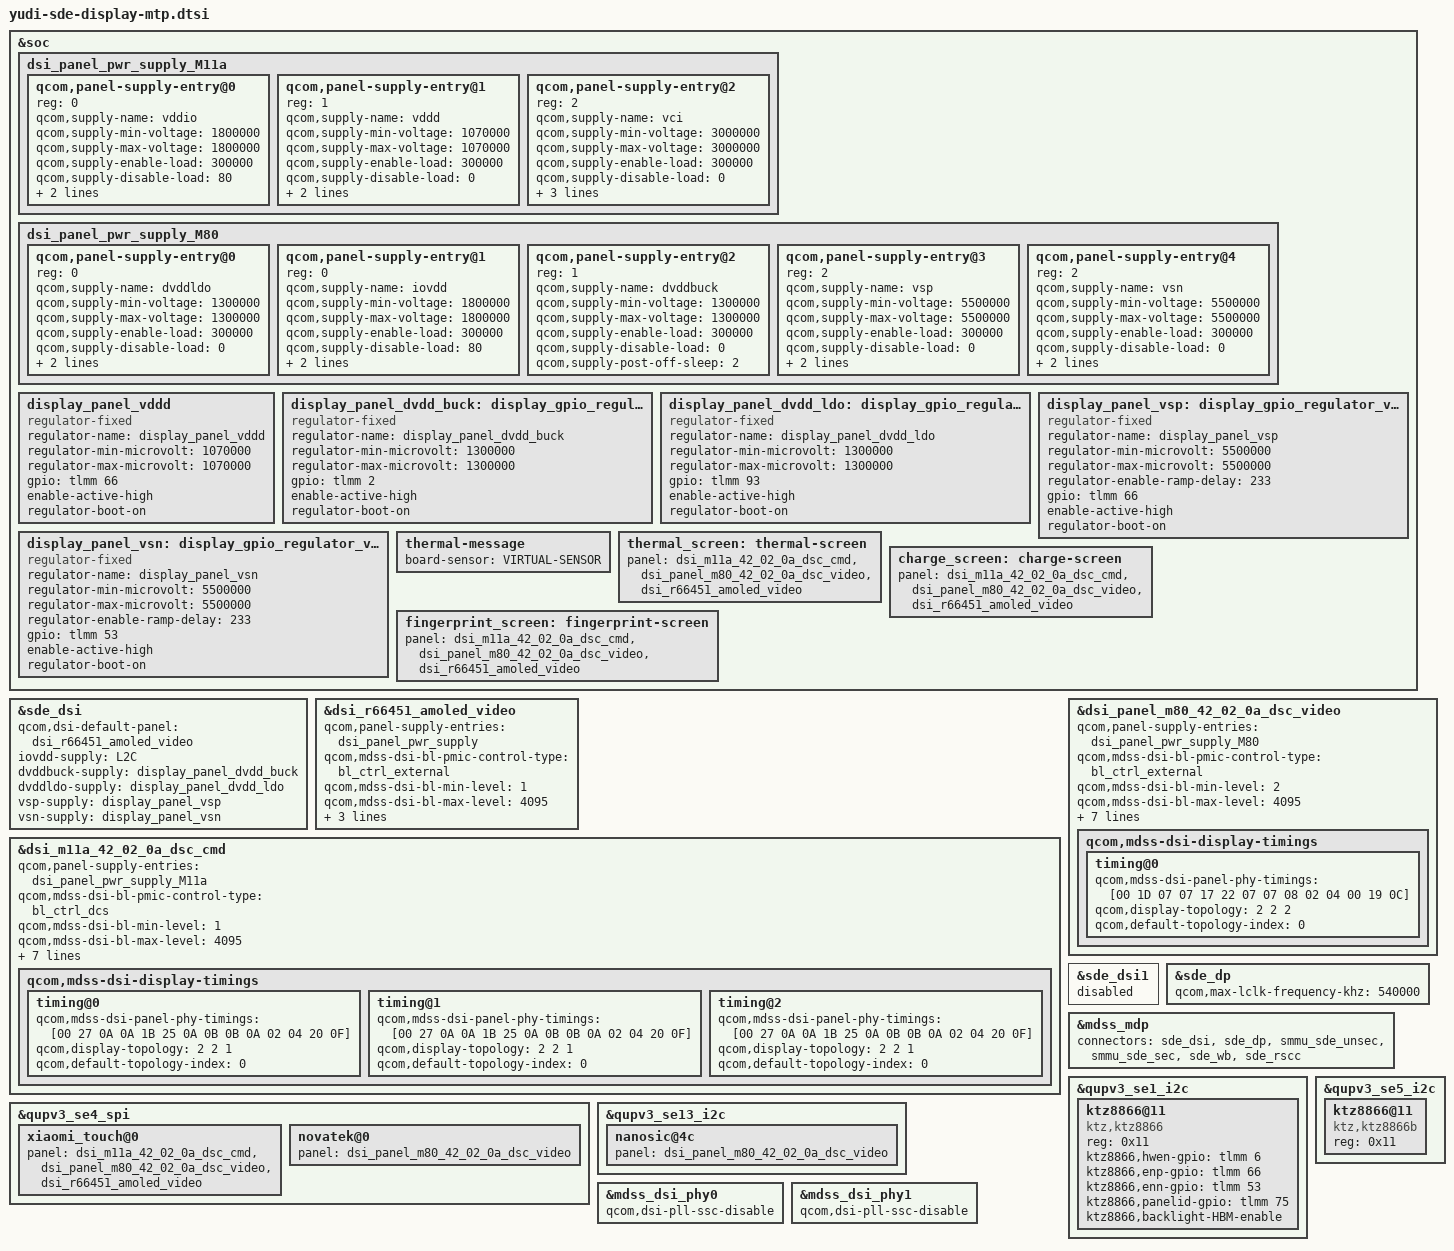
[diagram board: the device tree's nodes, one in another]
#include "cape-sde-display.dtsi"
#include "dsi-panel-m11a-42-02-0a-dsc-cmd.dtsi"
#include "dsi-panel-m80-42-02-0a-dsc-video.dtsi"

&soc {
	dsi_panel_pwr_supply_M11a: dsi_panel_pwr_supply_M11a {
		#address-cells = <1>;
		#size-cells = <0>;
		qcom,panel-supply-entry@0 {
			reg = <0>;
			qcom,supply-name = "vddio";
			qcom,supply-min-voltage = <1800000>;
			qcom,supply-max-voltage = <1800000>;
			qcom,supply-enable-load = <300000>;
			qcom,supply-disable-load = <80>;
			qcom,supply-post-on-sleep = <20>;
			qcom,supply-post-off-sleep = <10>;
		};
		qcom,panel-supply-entry@1 {
			reg = <1>;
			qcom,supply-name = "vddd";
			qcom,supply-min-voltage = <1070000>;
			qcom,supply-max-voltage = <1070000>;
			qcom,supply-enable-load = <300000>;
			qcom,supply-disable-load = <0>;
			qcom,supply-post-on-sleep = <20>;
			qcom,supply-post-off-sleep = <10>;
		};
		qcom,panel-supply-entry@2 {
			reg = <2>;
			qcom,supply-name = "vci";
			qcom,supply-min-voltage = <3000000>;
			qcom,supply-max-voltage = <3000000>;
			qcom,supply-enable-load = <300000>;
			qcom,supply-disable-load = <0>;
			qcom,supply-post-on-sleep = <15>;
			qcom,supply-pre-on-sleep = <10>;
			qcom,supply-post-off-sleep = <10>;
		};
	};
};

&soc {
	dsi_panel_pwr_supply_M80: dsi_panel_pwr_supply_M80 {
		#address-cells = <1>;
		#size-cells = <0>;
		qcom,panel-supply-entry@0 {
			reg = <0>;
			qcom,supply-name = "dvddldo";
			qcom,supply-min-voltage = <1300000>;
			qcom,supply-max-voltage = <1300000>;
			qcom,supply-enable-load = <300000>;
			qcom,supply-disable-load = <0>;
			qcom,supply-post-on-sleep = <1>;
			qcom,supply-post-off-sleep = <1>;
		};

		qcom,panel-supply-entry@1 {
			reg = <0>;
			qcom,supply-name = "iovdd";
			qcom,supply-min-voltage = <1800000>;
			qcom,supply-max-voltage = <1800000>;
			qcom,supply-enable-load = <300000>;
			qcom,supply-disable-load = <80>;
			qcom,supply-post-on-sleep = <2>;
			qcom,supply-post-off-sleep = <2>;
		};
		qcom,panel-supply-entry@2 {
			reg = <1>;
			qcom,supply-name = "dvddbuck";
			qcom,supply-min-voltage = <1300000>;
			qcom,supply-max-voltage = <1300000>;
			qcom,supply-enable-load = <300000>;
			qcom,supply-disable-load = <0>;
			qcom,supply-post-off-sleep = <2>;
		};

		qcom,panel-supply-entry@3 {
			reg = <2>;
			qcom,supply-name = "vsp";
			qcom,supply-min-voltage = <5500000>;
			qcom,supply-max-voltage = <5500000>;
			qcom,supply-enable-load = <300000>;
			qcom,supply-disable-load = <0>;
			qcom,supply-post-on-sleep = <2>;
			qcom,supply-post-off-sleep = <2>;
		};

		qcom,panel-supply-entry@4 {
			reg = <2>;
			qcom,supply-name = "vsn";
			qcom,supply-min-voltage = <5500000>;
			qcom,supply-max-voltage = <5500000>;
			qcom,supply-enable-load = <300000>;
			qcom,supply-disable-load = <0>;
			qcom,supply-post-on-sleep = <2>;
			qcom,supply-post-off-sleep = <2>;
		};
	};
};

&soc {
	display_panel_vddd: display_panel_vddd {
		compatible = "regulator-fixed";
		regulator-name = "display_panel_vddd";
		regulator-min-microvolt = <1070000>;
		regulator-max-microvolt = <1070000>;
		gpio = <&tlmm 66 0>;
		enable-active-high;
		regulator-boot-on;
	};
	
	display_panel_dvdd_buck: display_gpio_regulator_dvdd_buck {
		compatible = "regulator-fixed";
		regulator-name = "display_panel_dvdd_buck";
		regulator-min-microvolt = <1300000>;
		regulator-max-microvolt = <1300000>;
		gpio = <&tlmm 2 0>;
		enable-active-high;
		regulator-boot-on;
	};

	display_panel_dvdd_ldo: display_gpio_regulator_dvdd_ldo {
		compatible = "regulator-fixed";
		regulator-name = "display_panel_dvdd_ldo";
		regulator-min-microvolt = <1300000>;
		regulator-max-microvolt = <1300000>;
		gpio = <&tlmm 93 0>;
		enable-active-high;
		regulator-boot-on;
	};

	display_panel_vsp: display_gpio_regulator_vsp {
		compatible = "regulator-fixed";
		regulator-name = "display_panel_vsp";
		regulator-min-microvolt = <5500000>;
		regulator-max-microvolt = <5500000>;
		regulator-enable-ramp-delay = <233>;
		gpio = <&tlmm 66 0>;
		enable-active-high;
		regulator-boot-on;
	};

	display_panel_vsn: display_gpio_regulator_vsn {
		compatible = "regulator-fixed";
		regulator-name = "display_panel_vsn";
		regulator-min-microvolt = <5500000>;
		regulator-max-microvolt = <5500000>;
		regulator-enable-ramp-delay = <233>;
		gpio = <&tlmm 53 0>;
		enable-active-high;
		regulator-boot-on;
	};
};
&sde_dsi {
	qcom,dsi-default-panel = <&dsi_r66451_amoled_video>;
	iovdd-supply = <&L2C>;
	dvddbuck-supply = <&display_panel_dvdd_buck>;
	dvddldo-supply = <&display_panel_dvdd_ldo>;
	vsp-supply = <&display_panel_vsp>;
	vsn-supply = <&display_panel_vsn>;
};
&dsi_r66451_amoled_video {
	qcom,panel-supply-entries = <&dsi_panel_pwr_supply>;
	qcom,mdss-dsi-bl-pmic-control-type = "bl_ctrl_external";
	qcom,mdss-dsi-bl-min-level = <1>;
	qcom,mdss-dsi-bl-max-level = <4095>;
	qcom,mdss-brightness-max-level = <255>;
	qcom,mdss-dsi-bl-inverted-dbv;
	qcom,platform-reset-gpio = <&tlmm 0 0>;
};
&dsi_m11a_42_02_0a_dsc_cmd {
	qcom,panel-supply-entries = <&dsi_panel_pwr_supply_M11a>;
	qcom,mdss-dsi-bl-pmic-control-type = "bl_ctrl_dcs";
	qcom,mdss-dsi-bl-min-level = <1>;
	qcom,mdss-dsi-bl-max-level = <4095>;
	qcom,mdss-brightness-max-level = <4095>;
	qcom,mdss-dsi-bl-inverted-dbv;
	qcom,platform-reset-gpio = <&tlmm 0 0>;
};
&dsi_m11a_42_02_0a_dsc_cmd  {
	qcom,ulps-enabled;
	qcom,mdss-dsi-panel-vsync-delay;
	qcom,dsi-select-clocks = "pll_byte_clk0", "pll_dsi_clk0";
		qcom,mdss-dsi-display-timings {
		/* 60 Hz */
		timing@0{
			qcom,mdss-dsi-panel-phy-timings = [00 27 0A 0A 1B 25 0A
				0B 0B 0A 02 04 20 0F];
			qcom,display-topology = <2 2 1>;
			qcom,default-topology-index = <0>;
		};
		/* 90Hz */
		timing@1{
				qcom,mdss-dsi-panel-phy-timings = [00 27 0A 0A 1B 25 0A
						0B 0B 0A 02 04 20 0F];
				qcom,display-topology = <2 2 1>;
				qcom,default-topology-index = <0>;
		};
		/* 120Hz */
		timing@2{
				qcom,mdss-dsi-panel-phy-timings = [00 27 0A 0A 1B 25 0A
						0B 0B 0A 02 04 20 0F];
				qcom,display-topology = <2 2 1>;
				qcom,default-topology-index = <0>;
		};
	};
};

&dsi_panel_m80_42_02_0a_dsc_video {
	qcom,panel-supply-entries = <&dsi_panel_pwr_supply_M80>;
	qcom,mdss-dsi-bl-pmic-control-type = "bl_ctrl_external";
	qcom,mdss-dsi-bl-min-level = <2>;
	qcom,mdss-dsi-bl-max-level = <4095>;
	qcom,mdss-brightness-max-level = <4095>;
	qcom,mdss-brightness-init-level = <307>;
	qcom,platform-reset-gpio = <&tlmm 0 0>;
};

&dsi_panel_m80_42_02_0a_dsc_video {
	qcom,dsi-ctrl-num = <0 1>;
	qcom,dsi-phy-num = <0 1>;
	qcom,dsi-select-clocks = "pll_byte_clk0", "pll_dsi_clk0";
	qcom,mdss-dsi-display-timings {
		timing@0 {
			qcom,mdss-dsi-panel-phy-timings = [00 1D 07 07 17 22 07 
						07 08 02 04 00 19 0C];
			qcom,display-topology = <2 2 2>;
			qcom,default-topology-index = <0>;
		};
	};
};


&sde_dsi1 {
	status = "disabled";
};

&sde_dp {
	status = "ok";
	qcom,max-lclk-frequency-khz = <540000>;
};

&mdss_mdp {
	connectors = <&sde_dsi &sde_dp &smmu_sde_unsec &smmu_sde_sec &sde_wb &sde_rscc>;
};

&qupv3_se4_spi {
	xiaomi_touch@0  {
		panel = <&dsi_m11a_42_02_0a_dsc_cmd
			&dsi_panel_m80_42_02_0a_dsc_video
			&dsi_r66451_amoled_video>;
	};
};

/*M80 Backlight Driver SE 1 pin mappings */
&qupv3_se1_i2c {
	status = "ok";
	ktz8866@11 {
		compatible = "ktz,ktz8866";
		status = "ok";
		reg = <0x11>;
		ktz8866,hwen-gpio = <&tlmm 6 0x00>;
		ktz8866,enp-gpio = <&tlmm 66 0x00>;
		ktz8866,enn-gpio = <&tlmm 53 0x00>;
		ktz8866,panelid-gpio = <&tlmm 75 0x00>;
		ktz8866,backlight-HBM-enable;
	};
};

/*M80 Backlight Driver SE 5 pin mappings */
&qupv3_se5_i2c {
	status = "ok";
	ktz8866@11 {
		compatible = "ktz,ktz8866b";
		status = "ok";
		reg = <0x11>;
	};
};

&soc {
	thermal-message {
		board-sensor = "VIRTUAL-SENSOR";
	};
	thermal_screen: thermal-screen {
		panel = <&dsi_m11a_42_02_0a_dsc_cmd
			&dsi_panel_m80_42_02_0a_dsc_video
			&dsi_r66451_amoled_video>;
	};
	charge_screen: charge-screen {
		panel = <&dsi_m11a_42_02_0a_dsc_cmd
			&dsi_panel_m80_42_02_0a_dsc_video
			&dsi_r66451_amoled_video>;
	};
	fingerprint_screen: fingerprint-screen {
		panel = <&dsi_m11a_42_02_0a_dsc_cmd
			&dsi_panel_m80_42_02_0a_dsc_video
			&dsi_r66451_amoled_video>;
	};
};

/* TP Start */
&qupv3_se4_spi {
	novatek@0 {
		panel = <&dsi_panel_m80_42_02_0a_dsc_video>;
	};
};
/* TP End */

/* keyboard Start */
&qupv3_se13_i2c {
  nanosic@4c {
    panel = <&dsi_panel_m80_42_02_0a_dsc_video>;
	};
};
/* keyboard End   */

/* close ssc */
&mdss_dsi_phy0 {
	qcom,dsi-pll-ssc-disable;
};

&mdss_dsi_phy1 {
	qcom,dsi-pll-ssc-disable;
};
